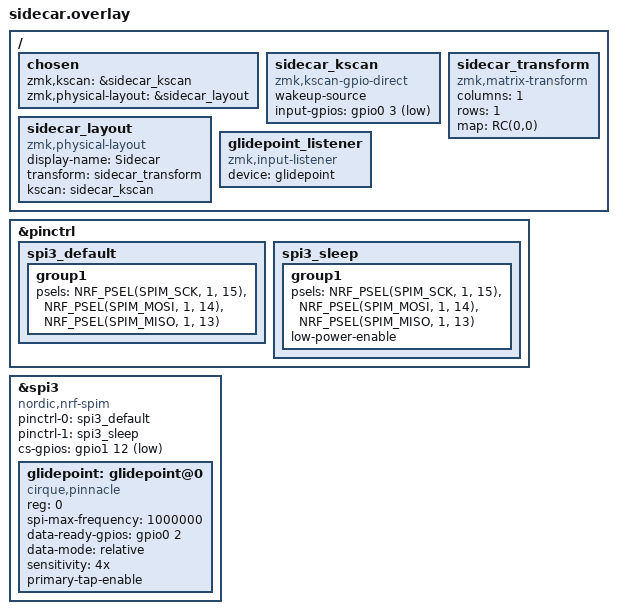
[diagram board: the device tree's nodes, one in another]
#include <dt-bindings/zmk/matrix_transform.h>
#include <dt-bindings/zmk/input_transform.h>
#include <zephyr/dt-bindings/input/input-event-codes.h>

&pinctrl {
    spi3_default: spi3_default {
        group1 {
            psels = <NRF_PSEL(SPIM_SCK, 1, 15)>,
                    <NRF_PSEL(SPIM_MOSI, 1, 14)>,
                    <NRF_PSEL(SPIM_MISO, 1, 13)>;
        };
    };

    spi3_sleep: spi3_sleep {
        group1 {
            psels = <NRF_PSEL(SPIM_SCK, 1, 15)>,
                    <NRF_PSEL(SPIM_MOSI, 1, 14)>,
                    <NRF_PSEL(SPIM_MISO, 1, 13)>;
            low-power-enable;
        };
    };
};

&spi3 {
    compatible = "nordic,nrf-spim";
    status = "okay";
    pinctrl-0 = <&spi3_default>;
    pinctrl-1 = <&spi3_sleep>;
    pinctrl-names = "default", "sleep";
    cs-gpios = <&gpio1 12 GPIO_ACTIVE_LOW>;

    glidepoint: glidepoint@0 {
        compatible = "cirque,pinnacle";
        reg = <0>;
        spi-max-frequency = <1000000>;
        status = "okay";
        data-ready-gpios = <&gpio0 2 GPIO_ACTIVE_HIGH>;
        data-mode = "relative";
        sensitivity = "4x";
        primary-tap-enable;
    };
};

/ {
    chosen {
        zmk,kscan = &sidecar_kscan;
        zmk,physical-layout = &sidecar_layout;
    };

    sidecar_kscan: sidecar_kscan {
        compatible = "zmk,kscan-gpio-direct";
        wakeup-source;
        input-gpios = <&gpio0 3 (GPIO_ACTIVE_LOW | GPIO_PULL_UP)>;
    };

    sidecar_transform: sidecar_transform {
        compatible = "zmk,matrix-transform";
        columns = <1>;
        rows = <1>;
        map = <RC(0,0)>;
    };

    sidecar_layout: sidecar_layout {
        compatible = "zmk,physical-layout";
        display-name = "Sidecar";
        transform = <&sidecar_transform>;
        kscan = <&sidecar_kscan>;
    };

    glidepoint_listener: glidepoint_listener {
        compatible = "zmk,input-listener";
        device = <&glidepoint>;
    };
};
